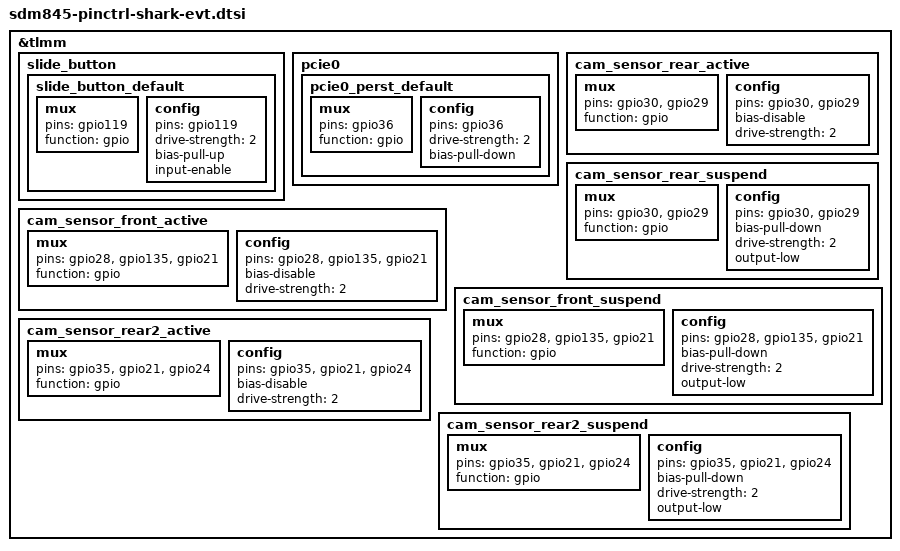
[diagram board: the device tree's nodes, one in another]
/*
 * Copyright (c) 2015-2016, The Linux Foundation. All rights reserved.
 *
 * This program is free software; you can redistribute it and/or modify
 * it under the terms of the GNU General Public License version 2 and
 * only version 2 as published by the Free Software Foundation.
 *
 * This program is distributed in the hope that it will be useful,
 * but WITHOUT ANY WARRANTY; without even the implied warranty of
 * MERCHANTABILITY or FITNESS FOR A PARTICULAR PURPOSE.  See the
 * GNU General Public License for more details.
 */

&tlmm {
	/********* slide button begin **********/
	slide_button {
		slide_button_default: slide_button_default {
			mux {
				pins = "gpio119";
				function = "gpio";
			};
			config {
				pins = "gpio119";
				drive-strength = <2>;
				bias-pull-up;
				input-enable;
			};
		};
	};
	/********* slide button end **********/

	//Fix camera gpio configuration conflict, terry.long@blackshark, 2017.11.08
	pcie0 {
		pcie0_perst_default {
			mux {
				pins = "gpio36";
				function = "gpio";
			};

			config {
				pins = "gpio36";
				drive-strength = <2>;
				bias-pull-down;
			};
		};
	};

	cam_sensor_rear_active {
		/* RESET, AVDD LDO */
		mux {
			pins = "gpio30","gpio29";
			function = "gpio";
		};

		config {
			pins = "gpio30","gpio29";
			bias-disable; /* No PULL */
			drive-strength = <2>; /* 2 MA */
		};
	};

	cam_sensor_rear_suspend {
		/* RESET, AVDD LDO */
		mux {
			pins = "gpio30","gpio29";
			function = "gpio";
		};

		config {
			pins = "gpio30","gpio29";
			bias-pull-down; /* PULL DOWN */
			drive-strength = <2>; /* 2 MA */
			output-low;
		};
	};

	cam_sensor_front_active {
		/* RESET  AVDD_LDO*/
		mux {
			pins = "gpio28", "gpio135", "gpio21";
			function = "gpio";
		};

		config {
			pins = "gpio28", "gpio135", "gpio21";
			bias-disable; /* No PULL */
			drive-strength = <2>; /* 2 MA */
		};
	};

	cam_sensor_front_suspend {
		/* RESET */
		mux {
			pins = "gpio28", "gpio135", "gpio21";
			function = "gpio";
		};

		config {
			pins = "gpio28", "gpio135", "gpio21";
			bias-pull-down; /* PULL DOWN */
			drive-strength = <2>; /* 2 MA */
			output-low;
		};
	};

	cam_sensor_rear2_active {
		/* RESET, STANDBY */
		mux {
			pins = "gpio35","gpio21","gpio24";
			function = "gpio";
		};

		config {
			pins = "gpio35","gpio21","gpio24";
			bias-disable; /* No PULL */
			drive-strength = <2>; /* 2 MA */
		};
	};

	cam_sensor_rear2_suspend {
		/* RESET, STANDBY */
		mux {
			pins = "gpio35","gpio21","gpio24";
			function = "gpio";
		};
		config {
			pins = "gpio35","gpio21","gpio24";
			bias-pull-down; /* PULL DOWN */
			drive-strength = <2>; /* 2 MA */
			output-low;
		};
	};
};
